# SA3_SS_PKTDMA_0_PKTDMA_RXCRT_44914000h register map
Vendor: Texas Instruments
Peripheral module from a debugger description file (folder AM275x).
Registers are 32-bit, read-write, reset 0x0 unless marked. A register's access mark holds for its fields unless they carry their own. Offsets are as the file gives them; lines under a group give offsets from that group; [hi:lo] are bit positions; {n}, {i} and the like mark numbered series; 'fields as' and 'values as' point back to an identical list; <NAME> marks a mode.

## pktdma_rxcrt
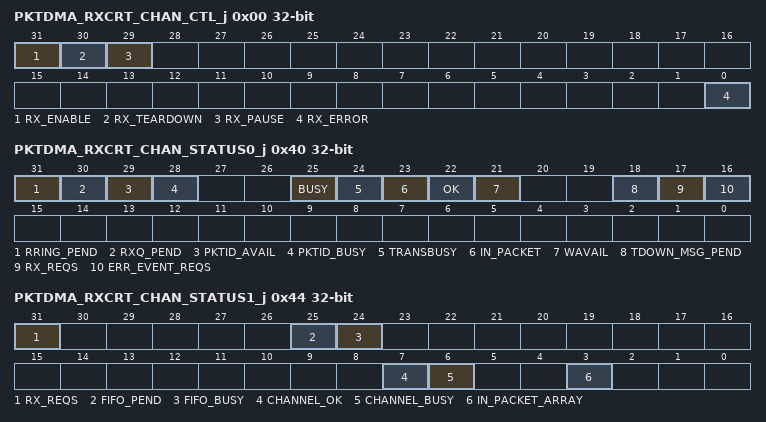
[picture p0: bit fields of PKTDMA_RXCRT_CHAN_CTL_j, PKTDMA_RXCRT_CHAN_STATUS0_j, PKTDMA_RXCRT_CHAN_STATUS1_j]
0x00 PKTDMA_RXCRT_CHAN_CTL_j — The Rx Channel Realtime Control Register contains real-time control and status information for the Rx DMA channel. The fields in this register can safely be changed while the channel is in operation.
  [31] RX_ENABLE — This field enables or disables the channel. Disabling a channel halts operation on the channel after the current block transfer is completed. Disabling a channel in the middle of a packet transfer may result in overflow conditions in the attached application and data loss. When a channel is disabled, the implementation may choose to reset all state for the channel. The pause bit should be asserted instead of clearing enable directly if the intent is to temporarily pause the channel. This field is encoded as follows: 0 = channel is disabled 1 = channel is enabled This field will be cleared by HW after a teardown is requested to indicate tha the channel teardown is complete. If the host is enabling a channel that is just being set up, the host must initialize all of the other channel configuration fields before setting this bit. Reset Source: rst_mod_g_rst_n
  [30] RX_TEARDOWN — This field indicates whether or not an Rx teardown operation is complete. This field should be cleared when a channel is initialized. This field will be set after a channel teardown is complete. Reset Source: rst_mod_g_rst_n
  [29] RX_PAUSE — Channel pause: Setting this bit will cause the channel to pause processing immediately. Reset Source: rst_mod_g_rst_n
  [0] RX_ERROR — Channel error: This bit will be set anytime an error has occurred on the channel. This bit is cleared when the channel is disabled and re-enabled. Reset Source: rst_mod_g_rst_n
0x40 PKTDMA_RXCRT_CHAN_STATUS0_j ro — The Status Register provides a read only view of channel status bits.
  [31] RRING_PEND — The channel ring has a descriptor Reset Source: rst_mod_g_rst_n
  [30] RXQ_PEND — The channel fifo is available Reset Source: rst_mod_g_rst_n
  [29] PKTID_AVAIL — The channel has an available packet id Reset Source: rst_mod_g_rst_n
  [28] PKTID_BUSY — There is an outstanding pktid for the channel Reset Source: rst_mod_g_rst_n
  [25] BUSY — The channel is busy Reset Source: rst_mod_g_rst_n
  [24] TRANSBUSY — The channel has an outstanding transaction Reset Source: rst_mod_g_rst_n
  [23] IN_PACKET — The channel is currently in a packet Reset Source: rst_mod_g_rst_n
  [22] OK — The channel is ready to be scheduled Reset Source: rst_mod_g_rst_n
  [21] WAVAIL — The fifo for the channel has space to place a burst size entry Reset Source: rst_mod_g_rst_n
  [18] TDOWN_MSG_PEND — A teardown message is pending Reset Source: rst_mod_g_rst_n
  [17] RX_REQS — The channel is sending a schedule request Reset Source: rst_mod_g_rst_n
  [16] ERR_EVENT_REQS — The channel is trying to schedule an error event Reset Source: rst_mod_g_rst_n
0x44 PKTDMA_RXCRT_CHAN_STATUS1_j ro — The Status Register provides a read only view of channel status bits.
  [31] RX_REQS — The channel is sending a schedule request Reset Source: rst_mod_g_rst_n
  [25] FIFO_PEND — The FIFO has enough data for a burst Reset Source: rst_mod_g_rst_n
  [24] FIFO_BUSY — The fifo has data Reset Source: rst_mod_g_rst_n
  [7] CHANNEL_OK — The channel is trying to schedule work Reset Source: rst_mod_g_rst_n
  [6] CHANNEL_BUSY — The channel has active work Reset Source: rst_mod_g_rst_n
  [3] IN_PACKET_ARRAY — The channel is in a packet Reset Source: rst_mod_g_rst_n
0x80 PKTDMA_RXCRT_CHAN_STDATA_j_k — The State Data Registers contain the current working state of the Rx DMA channel. These registers are provided so that the Host can determine the potential cause of an error or exception condition which was reported by the channel. These registers should not be accessed without reason while the PKTDMA is operating as accesses will cause performance to decrease as these MMRs are just providing a window into the actual state RAM
  [31:0] STATE_INFO — See Rx state mapping table Reset Source: rst_mod_g_rst_n
{0x200+4i} PKTDMA_RXCRT_CHAN_PEER{i}_j (i=0..15) — This register provides access to the remote peer's realtime register at {0x400+i}.
  [31:0] PEER_DATA — Peer realtime register data (varies by paired peer). Reset Source: rst_mod_g_rst_n
0x400 PKTDMA_RXCRT_CHAN_PCNT_j access not given — The statistics registers are supplied to give software applications operational progress status for the channel.
  [31:0] PCNT — Current completed packet count for the channel. Reset Source: rst_mod_g_rst_n (access R/WTD)
0x404 PKTDMA_RXCRT_CHAN_DCNT_j access not given — The statistics registers are supplied to give software applications operational progress status for the channel.
  [31:0] DCNT — Current dropped packet count for the channel. Reset Source: rst_mod_g_rst_n (access R/WTD)
0x408 PKTDMA_RXCRT_CHAN_BCNT_j access not given — The statistics registers are supplied to give software applications operational progress status for the channel.
  [31:0] BCNT — Current completed payload byte count for the channel. Reset Source: rst_mod_g_rst_n (access R/WTD)
0x410 PKTDMA_RXCRT_CHAN_SBCNT_j access not given — The statistics registers are supplied to give software applications operational progress status for the channel.
  [31:0] SBCNT — Current started byte count for the channel. Reset Source: rst_mod_g_rst_n (access R/WTD)
